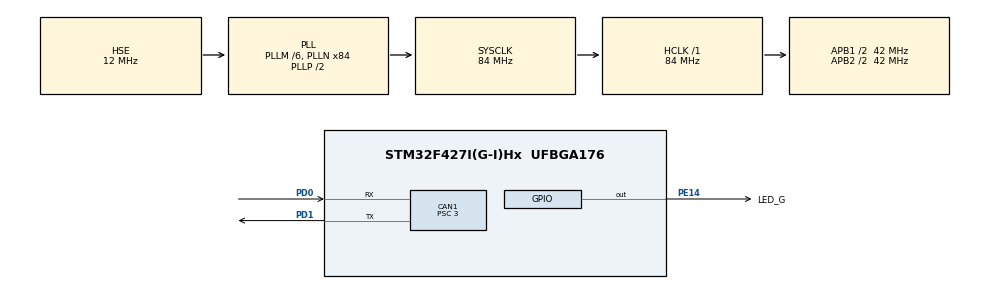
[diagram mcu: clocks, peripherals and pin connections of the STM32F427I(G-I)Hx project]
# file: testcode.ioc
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CAN1.BS1=CAN_BS1_10TQ
CAN1.BS2=CAN_BS2_3TQ
CAN1.CalculateBaudRate=1000000
CAN1.CalculateTimeBit=1000
CAN1.CalculateTimeQuantum=71.42857142857143
CAN1.Prescaler=3
Mcu.Family=STM32F4
Mcu.Name=STM32F427I(G-I)Hx
Mcu.Package=UFBGA176
NVIC.CAN1_RX0_IRQn=true\:0\:0\:false\:false\:true\:true\:true\:true
NVIC.PriorityGroup=NVIC_PRIORITYGROUP_4
PA13.Mode=Serial_Wire
PA13.Signal=SYS_JTMS-SWDIO
PA14.Mode=Serial_Wire
PA14.Signal=SYS_JTCK-SWCLK
PD0.Mode=CAN_Activate
PD0.Signal=CAN1_RX
PD1.Mode=CAN_Activate
PD1.Signal=CAN1_TX
PE14.GPIO_Label=LED_G
PE14.Signal=GPIO_Output
PH0/OSC_IN.Mode=HSE-External-Oscillator
PH0/OSC_IN.Signal=RCC_OSC_IN
PH1/OSC_OUT.Mode=HSE-External-Oscillator
PH1/OSC_OUT.Signal=RCC_OSC_OUT
ProjectManager.HeapSize=0x200
ProjectManager.StackSize=0x400
ProjectManager.TargetToolchain=MDK-ARM V5.32
RCC.48MHZClocksFreq_Value=42000000
RCC.AHBFreq_Value=84000000
RCC.APB1CLKDivider=RCC_HCLK_DIV2
RCC.APB1Freq_Value=42000000
RCC.APB1TimFreq_Value=84000000
RCC.APB2CLKDivider=RCC_HCLK_DIV2
RCC.APB2Freq_Value=42000000
RCC.APB2TimFreq_Value=84000000
RCC.CortexFreq_Value=84000000
RCC.HCLKFreq_Value=84000000
RCC.HSE_VALUE=12000000
RCC.HSI_VALUE=16000000
RCC.LSE_VALUE=32768
RCC.PLLM=6
RCC.PLLN=84
RCC.PLLSourceVirtual=RCC_PLLSOURCE_HSE
RCC.SYSCLKFreq_VALUE=84000000
RCC.SYSCLKSource=RCC_SYSCLKSOURCE_PLLCLK
RCC.VCOOutputFreq_Value=168000000
board=custom

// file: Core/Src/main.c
/* USER CODE BEGIN Header */
/**
  ******************************************************************************
  * @file           : main.c
  * @brief          : Main program body
  ******************************************************************************
  * @attention
  *
  * Copyright (c) 2024 STMicroelectronics.
  * All rights reserved.
  *
  * This software is licensed under terms that can be found in the LICENSE file
  * in the root directory of this software component.
  * If no LICENSE file comes with this software, it is provided AS-IS.
  *
  ******************************************************************************
  */
/* USER CODE END Header */
#include "main.h"
#include "can.h"
#include "gpio.h"
#include "M3508.h"

/* USER CODE BEGIN Includes */
uint8_t rx_buffer[8];
uint8_t tx_buffer[8];
M3508_Motor motor;
float Motor_ratio_ = 19;

/* USER CODE END Includes */

void SystemClock_Config(void);

int main(void)
{

  /* USER CODE BEGIN 1 */
  motor_init(&motor);
  /* USER CODE END 1 */

  /* MCU Configuration--------------------------------------------------------*/

  /* Reset of all peripherals, Initializes the Flash interface and the Systick. */
  HAL_Init();

  /* Configure the system clock */
  SystemClock_Config();

  /* Initialize all configured peripherals */
  MX_GPIO_Init();
  MX_CAN1_Init();
  /* USER CODE BEGIN 2 */

  //CAN1 configuration
  CAN_FilterTypeDef Filterconfig = {
    0x0000,
    0x0000,
    0x0000,
    0x0000,
    CAN_FilterFIFO0,
    0,
    CAN_FILTERMODE_IDMASK,
    CAN_FILTERSCALE_32BIT,
    ENABLE,
    0
  };
  HAL_CAN_ConfigFilter(&hcan1, &Filterconfig);
  HAL_CAN_Start(&hcan1);
  HAL_CAN_ActivateNotification(&hcan1, CAN_IT_RX_FIFO0_MSG_PENDING);

  //下为控制电流代码
  CAN_TxHeaderTypeDef tx_header = {
    .StdId = 0x200,
    .ExtId = 0x01,
    .IDE = CAN_ID_STD,
    .RTR = CAN_RTR_DATA,
    .DLC = 8,
    .TransmitGlobalTime = DISABLE
    };
  uint32_t tx_mailbox;
  uint8_t tx_buffer[8] = {0x11,0x22,0x33,0x44,0x55,0x66,0x77,0x88};

  /* USER CODE END 2 */

  /* Infinite loop */
  /* USER CODE BEGIN WHILE */
  while (1)
  {
    // HAL_CAN_AddTxMessage(&hcan1, &tx_header, tx_buffer, &tx_mailbox);//控制电机

    // HAL_Delay(5000);
    /* USER CODE END WHILE */

  }
}

void SystemClock_Config(void)
{
  RCC_OscInitTypeDef RCC_OscInitStruct = {0};
  RCC_ClkInitTypeDef RCC_ClkInitStruct = {0};

  /** Configure the main internal regulator output voltage
  */
  __HAL_RCC_PWR_CLK_ENABLE();
  __HAL_PWR_VOLTAGESCALING_CONFIG(PWR_REGULATOR_VOLTAGE_SCALE3);

  /** Initializes the RCC Oscillators according to the specified parameters
  * in the RCC_OscInitTypeDef structure.
  */
  RCC_OscInitStruct.OscillatorType = RCC_OSCILLATORTYPE_HSE;
  RCC_OscInitStruct.HSEState = RCC_HSE_ON;
  RCC_OscInitStruct.PLL.PLLState = RCC_PLL_ON;
  RCC_OscInitStruct.PLL.PLLSource = RCC_PLLSOURCE_HSE;
  RCC_OscInitStruct.PLL.PLLM = 6;
  RCC_OscInitStruct.PLL.PLLN = 84;
  RCC_OscInitStruct.PLL.PLLP = RCC_PLLP_DIV2;
  RCC_OscInitStruct.PLL.PLLQ = 4;
  if (HAL_RCC_OscConfig(&RCC_OscInitStruct) != HAL_OK)
  {
    Error_Handler();
  }

  /** Initializes the CPU, AHB and APB buses clocks
  */
  RCC_ClkInitStruct.ClockType = RCC_CLOCKTYPE_HCLK|RCC_CLOCKTYPE_SYSCLK
                              |RCC_CLOCKTYPE_PCLK1|RCC_CLOCKTYPE_PCLK2;
  RCC_ClkInitStruct.SYSCLKSource = RCC_SYSCLKSOURCE_PLLCLK;
  RCC_ClkInitStruct.AHBCLKDivider = RCC_SYSCLK_DIV1;
  RCC_ClkInitStruct.APB1CLKDivider = RCC_HCLK_DIV2;
  RCC_ClkInitStruct.APB2CLKDivider = RCC_HCLK_DIV2;

  if (HAL_RCC_ClockConfig(&RCC_ClkInitStruct, FLASH_LATENCY_2) != HAL_OK)
  {
    Error_Handler();
  }
}

void Error_Handler(void)
{
  __disable_irq();
  while (1)
  {
  }
}
